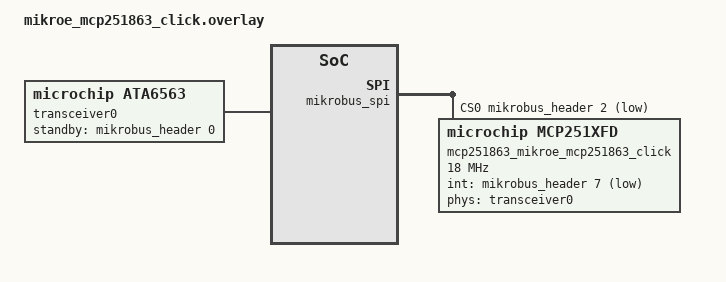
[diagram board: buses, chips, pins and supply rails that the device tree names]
/*
 * SPDX-FileCopyrightText: Copyright (c) 2026 Henrik Brix Andersen <henrik@brixandersen.dk>
 * SPDX-FileCopyrightText: Copyright (c) 2026 Navimatix GmbH
 * SPDX-FileCopyrightText: Copyright (c) 2026 TiaC Systems
 * SPDX-License-Identifier: Apache-2.0
 */

#include <zephyr/dt-bindings/gpio/gpio.h>
#include <freq.h>

/ {
	chosen {
		zephyr,canbus = &mcp251863_mikroe_mcp251863_click;
	};

	transceiver0: can-phy0 {
		compatible = "microchip,ata6563", "can-transceiver-gpio";
		standby-gpios = <&mikrobus_header 0 GPIO_ACTIVE_HIGH>;
		max-bitrate = <5000000>;
		#phy-cells = <0>;
	};
};

&mikrobus_spi {
	cs-gpios = <&mikrobus_header 2 GPIO_ACTIVE_LOW>;

	mcp251863_mikroe_mcp251863_click: can@0 {
		compatible = "microchip,mcp251xfd";
		reg = <0x0>;
		spi-max-frequency = <DT_FREQ_M(18)>;
		osc-freq = <DT_FREQ_M(40)>;
		int-gpios = <&mikrobus_header 7 GPIO_ACTIVE_LOW>;
		phys = <&transceiver0>;
		status = "okay";
	};
};
